# R7FA6T2BD register map
Vendor: Renesas Electronics Corporation; Series: RA6; File version: 1.40.00
CPU: CM33 r0p4, little endian, MPU, FPU, VTOR, 4 interrupt priority bits, 96 interrupts
Registers are 32-bit, read-write, reset 0x0 unless marked. A register's access mark holds for its fields unless they carry their own. Offsets are from the block's base; [hi:lo] are bit positions; {n}, {i} and the like mark numbered series.

## IIRFA — IIR filter accelerator
Base 0x40020000
0x00 IIRCPRCS ro — Channel Processing Status Register
  [15:0] CPRCS — Channel processing status bit
    0=The channel processing of the corresponding channel is not being performed; 1=The channel processing of the corresponding channel is being performed
0x04 IIRCPRCFF ro — Channel Processing Completion Flag Register
  [15:0] CPRCFF — Channel processing completion flag
    0=The channel processing of the corresponding channel is not completed; 1=The channel processing of the corresponding channel is completed
0x08 IIRORDYF ro — Output Data Preparation Completion Flag Register
  [15:0] ORDYF — Output data preparation completion flag
    0=The output data preparation of the corresponding channel is not completed; 1=The output data preparation of the corresponding channel is completed
0x0C IIRCERRF ro — Operation Error Flag Register
  [15:0] CERRF — Operation error flag
    0=No operation error has occurred in the corresponding channel; 1=An operation error has occurred in the corresponding channel
0x10 IIROPCNT — Operation Control Register
  [2:0] RND — Setting for the rounding mode for addition and multiplication
    0=Round to nearest; 1=Round toward zero; other=Others (Setting prohibited.)
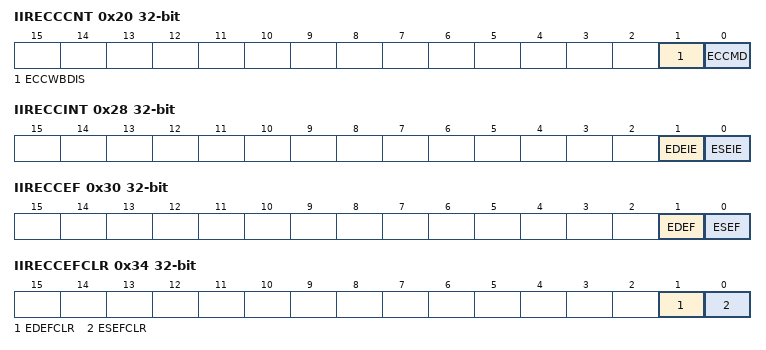
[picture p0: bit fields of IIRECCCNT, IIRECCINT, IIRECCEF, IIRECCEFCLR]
0x20 IIRECCCNT — ECC Control Register
  [1] ECCWBDIS — ECC-corrected data write-back disable bit
    0=The error-corrected data write-back is enabled; 1=The error-corrected data write-back is disabled
  [0] ECCMD — ECC setting bit
    0=The ECC error detection/correction function is disabled; 1=The ECC error detection/correction function is enabled
0x28 IIRECCINT — ECC Interrupt Enable Register
  [1] EDEIE — ECC 2-bit error interrupt enable bit
    0=The generation of ECC 2-bit error interrupt requests is disabled; 1=The generation of ECC 2-bit error interrupt requests is enabled
  [0] ESEIE — ECC 1-bit error interrupt enable bit
    0=The generation of ECC 1-bit error interrupt requests is disabled; 1=The generation of ECC 1-bit error interrupt requests is enabled
0x30 IIRECCEF ro — ECC Error Flag Register
  [1] EDEF — ECC 2-bit error flag
    0=No 2-bit ECC error is detected; 1=2-bit ECC error is detected
  [0] ESEF — ECC 1-bit error flag
    0=No 1-bit ECC error is detected; 1=1-bit ECC error is detected
0x34 IIRECCEFCLR wo — ECC Error Flag Clear Register
  [1] EDEFCLR — ECC 2-bit error status flag clear bit
    0=No effect; 1=Clears the EDEF flag of the IIRECCEF register
  [0] ESEFCLR — ECC 1-bit error flag clear bit
    0=No effect; 1=Clears the ESEF flag of the IIRECCEF register
0x38 IIRESEADR ro — ECC 1-bit Error Address Register
  [10:0] SEADR — Error address
0x3C IIREDEADR ro — ECC 2-bit Error Address Register
  [10:0] DEADR — Error address
{0x100+0x10*i} IIRCH{i}INP (i=0..15) wo reset not defined — Channel {i} Input Register
{0x104+0x10*i} IIRCH{i}OUT (i=0..15) ro — Channel {i} Output Register
{0x108+0x10*i} IIRCH{i}CNT (i=0..15) — Channel {i} Control Register
  [31:0] STGSEL — Stage selection bit
    0=The corresponding stage is not used for channel n; 1=The corresponding stage is used for channel n
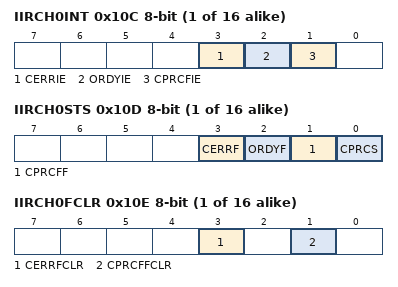
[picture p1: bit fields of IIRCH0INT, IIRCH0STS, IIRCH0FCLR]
{0x10C+0x10*i} IIRCH{i}INT (i=0..15) 8-bit — Channel {i} Interrupt Enable Register
  [3] CERRIE — Operation error interrupt enable bit
    0=The generation of operation error interrupt requests is disabled; 1=The generation of operation error interrupt requests is enabled
  [2] ORDYIE — Output data preparation completion interrupt enable bit
    0=The generation of output data preparation completion interrupt requests is disabled; 1=The generation of output data preparation completion interrupt requests is enabled
  [1] CPRCFIE — Channel processing completion interrupt enable bit
    0=The generation of channel processing completion interrupt requests is disabled; 1=The generation of channel processing completion interrupt requests is enabled
{0x10D+0x10*i} IIRCH{i}STS (i=0..15) 8-bit ro — Channel {i} Status Register
  [3] CERRF — Operation error flag
    0=No operation error has occurred; 1=An operation error has occurred
  [2] ORDYF — Output data preparation completion flag
    0=The output data preparation is not completed; 1=The output data preparation is completed
  [1] CPRCFF — Channel processing completion flag
    0=The channel processing is not completed; 1=The channel processing is completed
  [0] CPRCS — Channel processing status flag
    0=The channel processing is not being performed; 1=The channel processing is being performed
{0x10E+0x10*i} IIRCH{i}FCLR (i=0..15) 8-bit wo — Channel {i} Flag Clear Register
  [3] CERRFCLR — Operation error flag clear bit
    0=No effect; 1=Clears the CERRF flag of the IIRCHnSTS register
  [1] CPRCFFCLR — Channel processing completion flag clear bit
    0=No effect; 1=Clears the CPRCFF flag of the IIRCHnSTS register
{0x400+0x20*i} IIRSTG{i}B0 (i=0..31) reset not defined — Stage {i} Coefficient b0 Register
{0x404+0x20*i} IIRSTG{i}B1 (i=0..31) reset not defined — Stage {i} Coefficient b1 Register
{0x408+0x20*i} IIRSTG{i}B2 (i=0..31) reset not defined — Stage {i} Coefficient b2 Register
{0x40C+0x20*i} IIRSTG{i}A1 (i=0..31) reset not defined — Stage {i} Coefficient a1 Register
{0x410+0x20*i} IIRSTG{i}A2 (i=0..31) reset not defined — Stage {i} Coefficient a2 Register
{0x414+0x20*i} IIRSTG{i}D0 (i=0..31) reset not defined — Stage {i} Delay Data D0 Register
{0x418+0x20*i} IIRSTG{i}D1 (i=0..31) reset not defined — Stage {i} Delay Data D1 Register
